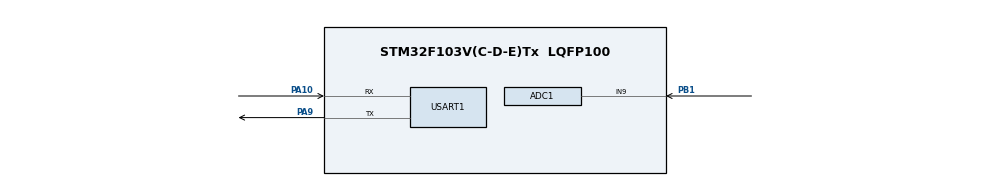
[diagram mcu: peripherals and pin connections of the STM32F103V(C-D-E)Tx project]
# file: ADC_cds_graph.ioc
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ADC1.Channel-0\#ChannelRegularConversion=ADC_CHANNEL_9
ADC1.ContinuousConvMode=ENABLE
ADC1.NbrOfConversionFlag=1
ADC1.Rank-0\#ChannelRegularConversion=1
ADC1.SamplingTime-0\#ChannelRegularConversion=ADC_SAMPLETIME_1CYCLE_5
ADC1.master=1
Dma.ADC1.0.Direction=DMA_PERIPH_TO_MEMORY
Dma.ADC1.0.Instance=DMA1_Channel1
Dma.ADC1.0.MemDataAlignment=DMA_MDATAALIGN_WORD
Dma.ADC1.0.MemInc=DMA_MINC_ENABLE
Dma.ADC1.0.Mode=DMA_NORMAL
Dma.ADC1.0.PeriphDataAlignment=DMA_PDATAALIGN_WORD
Dma.ADC1.0.PeriphInc=DMA_PINC_DISABLE
Dma.ADC1.0.Priority=DMA_PRIORITY_LOW
Dma.Request0=ADC1
Mcu.Family=STM32F1
Mcu.Name=STM32F103V(C-D-E)Tx
Mcu.Package=LQFP100
NVIC.DMA1_Channel1_IRQn=true\:0\:0\:false\:false\:true\:false\:true
NVIC.PriorityGroup=NVIC_PRIORITYGROUP_4
NVIC.USART1_IRQn=true\:0\:0\:false\:false\:true\:true\:true
OSC_IN.Mode=HSE-External-Oscillator
OSC_IN.Signal=RCC_OSC_IN
OSC_OUT.Mode=HSE-External-Oscillator
OSC_OUT.Signal=RCC_OSC_OUT
PA10.Mode=Asynchronous
PA10.Signal=USART1_RX
PA9.Mode=Asynchronous
PA9.Signal=USART1_TX
PB1.Signal=ADCx_IN9
ProjectManager.HeapSize=0x200
ProjectManager.StackSize=0x400
ProjectManager.TargetToolchain=STM32CubeIDE
RCC.APB1Freq_Value=8000000
RCC.APB2Freq_Value=8000000
SH.ADCx_IN9.0=ADC1_IN9,IN9
USART1.VirtualMode=VM_ASYNC
VP_SYS_VS_ND.Mode=No_Debug
board=custom

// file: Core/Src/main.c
/* USER CODE BEGIN Header */
/**
  ******************************************************************************
  * @file           : main.c
  * @brief          : Main program body
  ******************************************************************************
  * @attention
  *
  * <h2><center>&copy; Copyright (c) 2021 STMicroelectronics.
  * All rights reserved.</center></h2>
  *
  * This software component is licensed by ST under BSD 3-Clause license,
  * the "License"; You may not use this file except in compliance with the
  * License. You may obtain a copy of the License at:
  *                        opensource.org/licenses/BSD-3-Clause
  *
  ******************************************************************************
  */
/* USER CODE END Header */
#include "main.h"
#include "adc.h"
#include "dma.h"
#include "usart.h"
#include "gpio.h"
#include <stdio.h>

void SystemClock_Config(void);

int _write(int file, unsigned char* p, int len)
{
   HAL_UART_Transmit(&huart1, p, len, 10);
   return len;
}
#ifdef __GNUC__
#define PUTCHAR_PROTOTYPE int __io_putchar(int ch)
#else
#define PUTCHAR_PROTOTYPE int fputc(int ch, FILE *f)  //for printf
#endif
PUTCHAR_PROTOTYPE
{

  HAL_UART_Transmit(&huart1, (uint8_t *)&ch, 1, 0xFFFF);
  return ch;
}

int main(void)
{

  /* MCU Configuration--------------------------------------------------------*/

  /* Reset of all peripherals, Initializes the Flash interface and the Systick. */
  HAL_Init();

  /* Configure the system clock */
  SystemClock_Config();

  /* Initialize all configured peripherals */
  MX_GPIO_Init();
  MX_DMA_Init();
  MX_ADC1_Init();
  MX_USART1_UART_Init();
  /* USER CODE BEGIN 2 */
  setvbuf(stdout, NULL, _IONBF, 0);

  uint32_t ADC_Value_32[1]={0};
  uint16_t ADC_Value_16;

  /* USER CODE END 2 */

  /* Infinite loop */
  while (1)
  {

    /* USER CODE BEGIN 3 */
	  HAL_ADC_Start_DMA(&hadc1, ADC_Value_32, 1);
	  HAL_Delay(1000);
	  ADC_Value_16=(uint16_t)ADC_Value_32[0];
	  ADC_Value_16 &= 0xFFF;
	  printf("cds:%d\n", ADC_Value_16);
  }
  /* USER CODE END 3 */
}

void SystemClock_Config(void)
{
  RCC_OscInitTypeDef RCC_OscInitStruct = {0};
  RCC_ClkInitTypeDef RCC_ClkInitStruct = {0};
  RCC_PeriphCLKInitTypeDef PeriphClkInit = {0};

  /** Initializes the RCC Oscillators according to the specified parameters
  * in the RCC_OscInitTypeDef structure.
  */
  RCC_OscInitStruct.OscillatorType = RCC_OSCILLATORTYPE_HSI;
  RCC_OscInitStruct.HSIState = RCC_HSI_ON;
  RCC_OscInitStruct.HSICalibrationValue = RCC_HSICALIBRATION_DEFAULT;
  RCC_OscInitStruct.PLL.PLLState = RCC_PLL_NONE;
  if (HAL_RCC_OscConfig(&RCC_OscInitStruct) != HAL_OK)
  {
    Error_Handler();
  }
  /** Initializes the CPU, AHB and APB buses clocks
  */
  RCC_ClkInitStruct.ClockType = RCC_CLOCKTYPE_HCLK|RCC_CLOCKTYPE_SYSCLK
                              |RCC_CLOCKTYPE_PCLK1|RCC_CLOCKTYPE_PCLK2;
  RCC_ClkInitStruct.SYSCLKSource = RCC_SYSCLKSOURCE_HSI;
  RCC_ClkInitStruct.AHBCLKDivider = RCC_SYSCLK_DIV1;
  RCC_ClkInitStruct.APB1CLKDivider = RCC_HCLK_DIV1;
  RCC_ClkInitStruct.APB2CLKDivider = RCC_HCLK_DIV1;

  if (HAL_RCC_ClockConfig(&RCC_ClkInitStruct, FLASH_LATENCY_0) != HAL_OK)
  {
    Error_Handler();
  }
  PeriphClkInit.PeriphClockSelection = RCC_PERIPHCLK_ADC;
  PeriphClkInit.AdcClockSelection = RCC_ADCPCLK2_DIV2;
  if (HAL_RCCEx_PeriphCLKConfig(&PeriphClkInit) != HAL_OK)
  {
    Error_Handler();
  }
}

void Error_Handler(void)
{
  __disable_irq();
  while (1)
  {
  }
}

/************************ (C) COPYRIGHT STMicroelectronics *****END OF FILE****/
